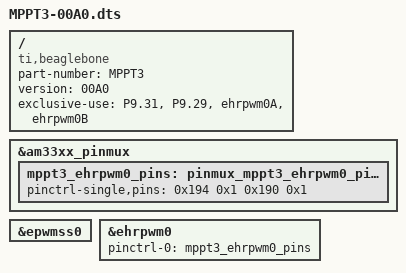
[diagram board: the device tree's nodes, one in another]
/*
 * Hacked together using Bacon Cape as an example
 *
 * This program is free software; you can redistribute it and/or modify
 * it under the terms of the GNU General Public License version 2 as
 * published by the Free Software Foundation.
 */
/dts-v1/;
/plugin/;

/ {
	compatible = "ti,beaglebone", "ti,beaglebone-black";

	/* identification */
	part-number = "MPPT3";
	version = "00A0";

	/* state the resources this cape uses */
	exclusive-use =
		/* the pin header uses */
//		"P9.39",	/* AIN0 */
//		"P9.37",	/* AIN2 */
//		"P9.38",	/* AIN3 */
//		"P9.33",	/* AIN4 */
//		"P9.35",	/* AIN6 */
		"P9.31",	/* pwm: ehrpwm0A */
		"P9.29",	/* pwm: ehrpwm0B */
		/* the hardware IP uses */
		/*"tscadc",*/
		"ehrpwm0A",
		"ehrpwm0B";

	fragment@0 {
		target = <&am33xx_pinmux>;
		__overlay__ {
			mppt3_ehrpwm0_pins: pinmux_mppt3_ehrpwm0_pins {
				pinctrl-single,pins = <
					0x194  0x1	/* P9_29 | MODE 1 */
					0x190  0x1	/* P9_31 | MODE 1 */
				>;
			};
		};
	};

	fragment@3 {
		target = <&epwmss0>;
		__overlay__ {
			status = "okay";
		};
	};
	fragment@6 {
		target = <&ehrpwm0>;
		__overlay__ {
			pinctrl-names = "default";
			pinctrl-0 = <&mppt3_ehrpwm0_pins>;
			status = "okay";
		};
	};
};

